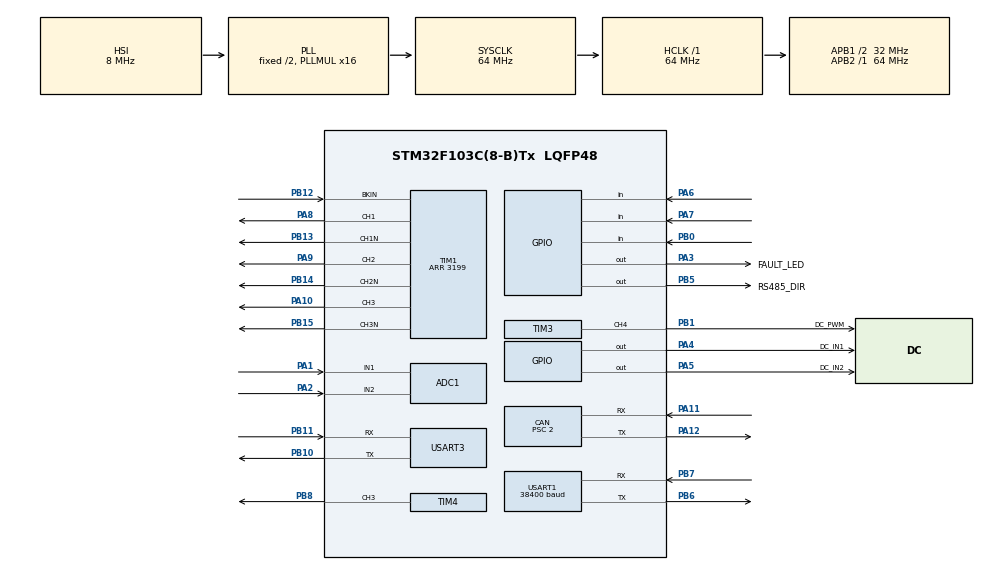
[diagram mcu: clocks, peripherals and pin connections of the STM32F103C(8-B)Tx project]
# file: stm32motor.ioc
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ADC1.Channel-3\#ChannelRegularConversion=ADC_CHANNEL_1
ADC1.Channel-4\#ChannelRegularConversion=ADC_CHANNEL_2
ADC1.EnableInjectedConversion=DISABLE
ADC1.InjNumberOfConversion=0
ADC1.NbrOfConversion=2
ADC1.NbrOfConversionFlag=1
ADC1.Rank-3\#ChannelRegularConversion=1
ADC1.Rank-4\#ChannelRegularConversion=2
ADC1.SamplingTime-3\#ChannelRegularConversion=ADC_SAMPLETIME_55CYCLES_5
ADC1.SamplingTime-4\#ChannelRegularConversion=ADC_SAMPLETIME_55CYCLES_5
ADC1.master=1
CAN.ABOM=ENABLE
CAN.BS1=CAN_BS1_11TQ
CAN.BS2=CAN_BS2_4TQ
CAN.CalculateBaudRate=1000000
CAN.CalculateTimeBit=1000
CAN.CalculateTimeQuantum=62.5
CAN.NART=ENABLE
CAN.Prescaler=2
Dma.ADC1.0.Direction=DMA_PERIPH_TO_MEMORY
Dma.ADC1.0.Instance=DMA1_Channel1
Dma.ADC1.0.MemDataAlignment=DMA_MDATAALIGN_HALFWORD
Dma.ADC1.0.MemInc=DMA_MINC_ENABLE
Dma.ADC1.0.Mode=DMA_CIRCULAR
Dma.ADC1.0.PeriphDataAlignment=DMA_PDATAALIGN_HALFWORD
Dma.ADC1.0.PeriphInc=DMA_PINC_DISABLE
Dma.ADC1.0.Priority=DMA_PRIORITY_LOW
Dma.Request0=ADC1
Mcu.Family=STM32F1
Mcu.Name=STM32F103C(8-B)Tx
Mcu.Package=LQFP48
NVIC.DMA1_Channel1_IRQn=true\:0\:0\:false\:false\:true\:false\:true
NVIC.PriorityGroup=NVIC_PRIORITYGROUP_4
NVIC.TIM1_BRK_IRQn=true\:0\:0\:false\:false\:true\:true\:true
NVIC.USART1_IRQn=true\:6\:0\:false\:false\:true\:true\:true
NVIC.USART3_IRQn=true\:0\:0\:false\:false\:true\:true\:true
NVIC.USB_LP_CAN1_RX0_IRQn=true\:1\:0\:true\:false\:true\:true\:true
PA1.Signal=ADCx_IN1
PA10.GPIO_Speed=GPIO_SPEED_FREQ_MEDIUM
PA10.Signal=S_TIM1_CH3
PA11.Mode=CAN_Activate
PA11.Signal=CAN_RX
PA12.Mode=CAN_Activate
PA12.Signal=CAN_TX
PA13.Mode=Serial_Wire
PA13.Signal=SYS_JTMS-SWDIO
PA14.Mode=Serial_Wire
PA14.Signal=SYS_JTCK-SWCLK
PA2.Signal=ADCx_IN2
PA3.GPIO_Label=FAULT_LED
PA3.Signal=GPIO_Output
PA4.GPIO_Label=DC_IN1
PA4.Signal=GPIO_Output
PA5.GPIO_Label=DC_IN2
PA5.Signal=GPIO_Output
PA6.GPIO_PuPd=GPIO_NOPULL
PA6.Signal=GPIO_Input
PA7.Signal=GPIO_Input
PA8.GPIO_Speed=GPIO_SPEED_FREQ_MEDIUM
PA8.Signal=S_TIM1_CH1
PA9.GPIO_Speed=GPIO_SPEED_FREQ_MEDIUM
PA9.Signal=S_TIM1_CH2
PB0.Signal=GPIO_Input
PB1.GPIO_Label=DC_PWM
PB1.GPIO_Speed=GPIO_SPEED_FREQ_MEDIUM
PB1.Signal=S_TIM3_CH4
PB10.Mode=Asynchronous
PB10.Signal=USART3_TX
PB11.Mode=Asynchronous
PB11.Signal=USART3_RX
PB12.Mode=Activate-Break-Input
PB12.Signal=TIM1_BKIN
PB13.GPIO_Speed=GPIO_SPEED_FREQ_MEDIUM
PB13.Mode=PWM Generation1 CH1 CH1N
PB13.Signal=TIM1_CH1N
PB14.GPIO_Speed=GPIO_SPEED_FREQ_MEDIUM
PB14.Mode=PWM Generation2 CH2 CH2N
PB14.Signal=TIM1_CH2N
PB15.GPIO_Speed=GPIO_SPEED_FREQ_MEDIUM
PB15.Mode=PWM Generation3 CH3 CH3N
PB15.Signal=TIM1_CH3N
PB5.GPIO_Label=RS485_DIR
PB5.Signal=GPIO_Output
PB6.Mode=Asynchronous
PB6.Signal=USART1_TX
PB7.Mode=Asynchronous
PB7.Signal=USART1_RX
PB8.Signal=S_TIM4_CH3
ProjectManager.HeapSize=0x200
ProjectManager.StackSize=0x400
ProjectManager.TargetToolchain=MDK-ARM V5.32
RCC.ADCPresc=RCC_ADCPCLK2_DIV6
RCC.AHBFreq_Value=64000000
RCC.APB1CLKDivider=RCC_HCLK_DIV2
RCC.APB1Freq_Value=32000000
RCC.APB1TimFreq_Value=64000000
RCC.APB2Freq_Value=64000000
RCC.APB2TimFreq_Value=64000000
RCC.HCLKFreq_Value=64000000
RCC.PLLMUL=RCC_PLL_MUL16
RCC.SYSCLKFreq_VALUE=64000000
RCC.SYSCLKSource=RCC_SYSCLKSOURCE_PLLCLK
RCC.USBFreq_Value=64000000
SH.ADCx_IN1.0=ADC1_IN1,IN1
SH.ADCx_IN2.0=ADC1_IN2,IN2
SH.S_TIM1_CH1.0=TIM1_CH1,PWM Generation1 CH1 CH1N
SH.S_TIM1_CH2.0=TIM1_CH2,PWM Generation2 CH2 CH2N
SH.S_TIM1_CH3.0=TIM1_CH3,PWM Generation3 CH3 CH3N
SH.S_TIM3_CH4.0=TIM3_CH4,PWM Generation4 CH4
SH.S_TIM4_CH3.0=TIM4_CH3,PWM Generation3 CH3
TIM1.AutomaticOutput=TIM_AUTOMATICOUTPUT_DISABLE
TIM1.BreakPolarity=TIM_BREAKPOLARITY_LOW
TIM1.Channel-Output\ Compare4\ No\ Output=TIM_CHANNEL_4
TIM1.Channel-PWM\ Generation1\ CH1\ CH1N=TIM_CHANNEL_1
TIM1.Channel-PWM\ Generation2\ CH2\ CH2N=TIM_CHANNEL_2
TIM1.Channel-PWM\ Generation3\ CH3\ CH3N=TIM_CHANNEL_3
TIM1.OC4Preload=DISABLE
TIM1.OCPolarity_4=TIM_OCPOLARITY_HIGH
TIM1.Period=3199
TIM1.Pulse-Output\ Compare4\ No\ Output=256
TIM2.Prescaler=63
TIM3.Channel-PWM\ Generation4\ CH4=TIM_CHANNEL_4
TIM3.Period=3199
TIM4.Channel-PWM\ Generation3\ CH3=TIM_CHANNEL_3
TIM4.Period=19999
TIM4.Prescaler=63
TIM4.Pulse-PWM\ Generation3\ CH3=1500
USART1.BaudRate=38400
USART1.VirtualMode=VM_ASYNC
USART3.VirtualMode=VM_ASYNC
VP_TIM1_VS_ClockSourceINT.Mode=Internal
VP_TIM1_VS_no_output4.Mode=Output Compare4 No Output
VP_TIM2_VS_ClockSourceINT.Mode=Internal
VP_TIM3_VS_ClockSourceINT.Mode=Internal
VP_TIM4_VS_ClockSourceINT.Mode=Internal
board=custom

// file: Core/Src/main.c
/* USER CODE BEGIN Header */
/**
  ******************************************************************************
  * @file           : main.c
  * @brief          : Main program body
  ******************************************************************************
  * @attention
  *
  * Copyright (c) 2026 STMicroelectronics.
  * All rights reserved.
  *
  * This software is licensed under terms that can be found in the LICENSE file
  * in the root directory of this software component.
  * If no LICENSE file comes with this software, it is provided AS-IS.
  *
  ******************************************************************************
  */
/* USER CODE END Header */
#include "main.h"
#include "adc.h"
#include "can.h"
#include "dma.h"
#include "tim.h"
#include "usart.h"
#include "gpio.h"

/* USER CODE BEGIN Includes */
#include "motor_app.h"
/* USER CODE END Includes */

void SystemClock_Config(void);

int main(void)
{

  /* MCU Configuration--------------------------------------------------------*/

  /* Reset of all peripherals, Initializes the Flash interface and the Systick. */
  HAL_Init();

  /* Configure the system clock */
  SystemClock_Config();

  /* Initialize all configured peripherals */
  MX_GPIO_Init();
  MX_CAN_Init();
  MX_TIM1_Init();
  MX_TIM2_Init();
  MX_TIM3_Init();
  MX_TIM4_Init();
  MX_USART1_UART_Init();
  MX_USART3_UART_Init();
  MX_DMA_Init();
  MX_ADC1_Init();
  /* USER CODE BEGIN 2 */
  if (MotorApp_Init() != HAL_OK)
  {
    Error_Handler();
  }
  /* USER CODE END 2 */

  /* Infinite loop */
  while (1)
  {

    /* USER CODE BEGIN 3 */
    MotorApp_Process();
  }
  /* USER CODE END 3 */
}

void SystemClock_Config(void)
{
  RCC_OscInitTypeDef RCC_OscInitStruct = {0};
  RCC_ClkInitTypeDef RCC_ClkInitStruct = {0};
  RCC_PeriphCLKInitTypeDef PeriphClkInit = {0};

  /** Initializes the RCC Oscillators according to the specified parameters
  * in the RCC_OscInitTypeDef structure.
  */
  RCC_OscInitStruct.OscillatorType = RCC_OSCILLATORTYPE_HSI;
  RCC_OscInitStruct.HSIState = RCC_HSI_ON;
  RCC_OscInitStruct.HSICalibrationValue = RCC_HSICALIBRATION_DEFAULT;
  RCC_OscInitStruct.PLL.PLLState = RCC_PLL_ON;
  RCC_OscInitStruct.PLL.PLLSource = RCC_PLLSOURCE_HSI_DIV2;
  RCC_OscInitStruct.PLL.PLLMUL = RCC_PLL_MUL16;
  if (HAL_RCC_OscConfig(&RCC_OscInitStruct) != HAL_OK)
  {
    Error_Handler();
  }
  /** Initializes the CPU, AHB and APB buses clocks
  */
  RCC_ClkInitStruct.ClockType = RCC_CLOCKTYPE_HCLK|RCC_CLOCKTYPE_SYSCLK
                              |RCC_CLOCKTYPE_PCLK1|RCC_CLOCKTYPE_PCLK2;
  RCC_ClkInitStruct.SYSCLKSource = RCC_SYSCLKSOURCE_PLLCLK;
  RCC_ClkInitStruct.AHBCLKDivider = RCC_SYSCLK_DIV1;
  RCC_ClkInitStruct.APB1CLKDivider = RCC_HCLK_DIV2;
  RCC_ClkInitStruct.APB2CLKDivider = RCC_HCLK_DIV1;

  if (HAL_RCC_ClockConfig(&RCC_ClkInitStruct, FLASH_LATENCY_2) != HAL_OK)
  {
    Error_Handler();
  }
  PeriphClkInit.PeriphClockSelection = RCC_PERIPHCLK_ADC;
  PeriphClkInit.AdcClockSelection = RCC_ADCPCLK2_DIV6;
  if (HAL_RCCEx_PeriphCLKConfig(&PeriphClkInit) != HAL_OK)
  {
    Error_Handler();
  }
}

void Error_Handler(void)
{
  /* USER CODE BEGIN Error_Handler_Debug */
  /* User can add his own implementation to report the HAL error return state */
  __disable_irq();
  MotorApp_EmergencyStop();
  while (1)
  {
  }
  /* USER CODE END Error_Handler_Debug */
}
